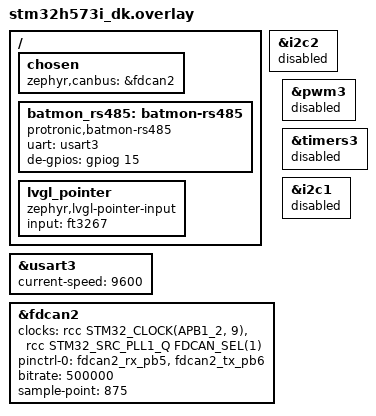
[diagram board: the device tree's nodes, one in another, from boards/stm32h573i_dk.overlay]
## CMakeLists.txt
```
cmake_minimum_required(VERSION 3.20.0)

find_package(Zephyr REQUIRED HINTS $ENV{ZEPHYR_BASE})
project(batmon LANGUAGES C VERSION 0.1.0)

target_include_directories(app PRIVATE src src/proto)

target_sources(app PRIVATE
  src/main.c
  src/can_rx.c
  src/proto/bm_proto.c
  src/proto/bm_json.c
  src/proto/bm_ydt.c
  src/proto/bm_serial.c
)

target_sources_ifdef(CONFIG_BATMON_RS485 app PRIVATE src/rs485.c)
target_sources_ifdef(CONFIG_BATMON_MQTT app PRIVATE src/net_mqtt.c)
target_sources_ifdef(CONFIG_BATMON_UI app PRIVATE src/ui.c)
target_sources_ifdef(CONFIG_SHELL app PRIVATE src/shell_cmds.c)
```

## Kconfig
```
mainmenu "batmon - battery CAN monitor"

menu "batmon"

config BATMON_DEVICE_ID
	string "Device id (MQTT client id, topic element, display)"
	default "batmon"

config BATMON_CAN_BITRATE
	int "CAN bitrate in bit/s"
	default 500000

config BATMON_CAN_LISTEN_ONLY
	bool "Listen-only: never acknowledge or transmit on the bus"
	default y
	help
	  Recommended when batmon is attached to a bus that already carries a
	  battery and an inverter. Disable only on the bench, where batmon is the
	  only counterpart of the battery.

config BATMON_BENCH_HEARTBEAT
	bool "Send the inverter keep-alive 0x305 once per second (bench mode)"
	depends on !BATMON_CAN_LISTEN_ONLY
	default n
	help
	  Many BMS firmwares stop reporting or open the contactor when no inverter
	  heartbeat is seen. With this option batmon plays the inverter role.

config BATMON_RAW_LOG
	bool "Log every received CAN frame"
	default n

config BATMON_MQTT
	bool "Publish telemetry over MQTT"
	default y

if BATMON_MQTT

config BATMON_MQTT_BROKER_HOST
	string "Broker host name or IPv4 address"
	default "192.168.1.10"

config BATMON_MQTT_BROKER_PORT
	int "Broker TCP port"
	default 1883

config BATMON_MQTT_USERNAME
	string "User name (ThingsBoard: device access token)"
	default ""

config BATMON_MQTT_PASSWORD
	string "Password"
	default ""

config BATMON_MQTT_INTERVAL_SEC
	int "Publish interval in seconds"
	default 5
	range 1 3600

choice BATMON_MQTT_MODE
	prompt "Topic and payload scheme"
	default BATMON_MQTT_MODE_GENERIC

config BATMON_MQTT_MODE_GENERIC
	bool "Generic: <prefix>/<id>/state JSON, <prefix>/<id>/status LWT"

config BATMON_MQTT_MODE_THINGSBOARD
	bool "ThingsBoard device API: v1/devices/me/telemetry (flat JSON)"

endchoice

config BATMON_MQTT_TOPIC_PREFIX
	string "Topic prefix (generic mode)"
	default "batmon"
	depends on BATMON_MQTT_MODE_GENERIC

config BATMON_HA_DISCOVERY
	bool "Publish Home Assistant MQTT discovery messages"
	default y
	depends on BATMON_MQTT_MODE_GENERIC

endif # BATMON_MQTT

menuconfig BATMON_RS485
	bool "RS485/UART BMS link (Pylontech/PACE/Seplos ASCII, JK-BMS, Seplos V3 Modbus)"
	default y
	depends on DT_HAS_PROTRONIC_BATMON_RS485_ENABLED
	select SERIAL
	select UART_INTERRUPT_DRIVEN
	select UART_USE_RUNTIME_CONFIGURE
	select RING_BUFFER
	help
	  Poll the BMS over its RS485 port (or listen to an inverter doing so) in
	  addition to the CAN bus. Needs a batmon-rs485 node in the devicetree.

if BATMON_RS485

config BATMON_RS485_LISTEN_ONLY
	bool "Listen only: decode the traffic between inverter and BMS, never transmit"
	default n

config BATMON_RS485_POLL_MS
	int "Poll interval in ms"
	default 2000
	range 200 60000

config BATMON_RS485_BAUD
	int "Fixed baud rate (0 = try 9600, 19200 and 115200)"
	default 0

config BATMON_RS485_ADDR
	int "Fixed pack address (-1 = try the usual ones)"
	default -1
	range -1 15
	help
	  Pylontech packs answer on address 2 (first module), PACE on 1,
	  Seplos on 0.

choice BATMON_RS485_FLAVOR
	prompt "Protocol"
	default BATMON_RS485_FLAVOR_AUTO

config BATMON_RS485_FLAVOR_AUTO
	bool "Auto-detect"

config BATMON_RS485_FLAVOR_PYLON
	bool "Pylontech ASCII (US2000/US3000/US5000, Force L)"

config BATMON_RS485_FLAVOR_PACE
	bool "PACE ASCII (FM-Solar/DelongTop, Gobel, SOK ...)"

config BATMON_RS485_FLAVOR_SEPLOS
	bool "Seplos V2 ASCII"

config BATMON_RS485_FLAVOR_JK
	bool "JK-BMS RS485"

config BATMON_RS485_FLAVOR_SEPLOS_V3
	bool "Seplos V3 Modbus RTU"

endchoice

config BATMON_JK_CURRENT_LEGACY
	bool "JK-BMS: old firmware current encoding (10000 - raw)"
	default n

endif # BATMON_RS485

config BATMON_UI
	bool "Status screen on the board display (LVGL)"
	default y
	depends on LVGL

endmenu

source "Kconfig.zephyr"
```

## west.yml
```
manifest:
  remotes:
    - name: zephyrproject-rtos
      url-base: https://github.com/zephyrproject-rtos

  projects:
    - name: zephyr
      remote: zephyrproject-rtos
      revision: v4.4.2
      import:
        name-allowlist:
          - cmsis
          - cmsis_6
          - hal_stm32
          - lvgl

  self:
    path: batmon
```

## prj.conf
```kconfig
# --- kernel / debug ---------------------------------------------------------
CONFIG_MAIN_STACK_SIZE=4096
CONFIG_SYSTEM_WORKQUEUE_STACK_SIZE=2048
CONFIG_HEAP_MEM_POOL_SIZE=24576
CONFIG_LOG=y
CONFIG_LOG_BUFFER_SIZE=4096
CONFIG_SHELL=y
CONFIG_SHELL_STACK_SIZE=4096
CONFIG_DEVICE_SHELL=y
CONFIG_KERNEL_SHELL=y
CONFIG_HWINFO=y
CONFIG_GPIO=y
CONFIG_REBOOT=y
CONFIG_ENTROPY_GENERATOR=y

# --- RS485 ------------------------------------------------------------------
CONFIG_SERIAL=y
CONFIG_UART_INTERRUPT_DRIVEN=y
CONFIG_RING_BUFFER=y

# --- CAN --------------------------------------------------------------------
CONFIG_CAN=y
CONFIG_CAN_SHELL=y

# --- Ethernet / IP ----------------------------------------------------------
CONFIG_NETWORKING=y
CONFIG_NET_L2_ETHERNET=y
CONFIG_NET_IPV4=y
CONFIG_NET_IPV6=n
CONFIG_NET_ARP=y
CONFIG_NET_UDP=y
CONFIG_NET_TCP=y
CONFIG_NET_DHCPV4=y
CONFIG_NET_SOCKETS=y
CONFIG_NET_SOCKETS_POLL_MAX=4
CONFIG_DNS_RESOLVER=y
CONFIG_NET_MGMT=y
CONFIG_NET_MGMT_EVENT=y
CONFIG_NET_MGMT_EVENT_INFO=y
CONFIG_NET_SHELL=y
CONFIG_NET_PKT_RX_COUNT=12
CONFIG_NET_PKT_TX_COUNT=12
CONFIG_NET_BUF_RX_COUNT=48
CONFIG_NET_BUF_TX_COUNT=48

# --- MQTT -------------------------------------------------------------------
CONFIG_MQTT_LIB=y
CONFIG_MQTT_KEEPALIVE=60

# --- display / LVGL ---------------------------------------------------------
CONFIG_DISPLAY=y
CONFIG_DISPLAY_LOG_LEVEL_ERR=y
CONFIG_INPUT=y
CONFIG_LVGL=y
CONFIG_LV_Z_MEM_POOL_SIZE=32768
CONFIG_LV_Z_VDB_SIZE=20
CONFIG_LV_COLOR_DEPTH_16=y
CONFIG_LV_USE_LABEL=y
CONFIG_LV_USE_BAR=y
CONFIG_LV_USE_ARC=y
CONFIG_LV_USE_CHART=y
CONFIG_LV_USE_BUTTON=y
CONFIG_LV_USE_TABVIEW=y
CONFIG_LV_FONT_MONTSERRAT_14=y
CONFIG_LV_FONT_MONTSERRAT_20=y
CONFIG_LV_FONT_MONTSERRAT_32=y
CONFIG_LV_FONT_DEFAULT_MONTSERRAT_14=y
```

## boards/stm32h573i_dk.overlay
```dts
/*
 * batmon on the STM32H573I-DK
 *
 * The Discovery kit has no CAN transceiver on board. FDCAN2 is routed to the
 * Arduino header, so a small 3.3 V transceiver breakout (SN65HVD230, TJA1051T/3,
 * MCP2562FD ...) connects directly:
 *
 *   PB5  FDCAN2_RX  -> Arduino D3   (transceiver RXD)
 *   PB6  FDCAN2_TX  -> Arduino D15  (transceiver TXD, the pin labelled SCL)
 *   3V3 / GND       -> transceiver supply (3.3 V logic!)
 *
 * PB5/PB6 are otherwise TIM3_CH2 (D3 PWM) and I2C1_SCL (Arduino I2C), both unused
 * by batmon and therefore disabled here.
 *
 * Alternative: the board devicetree wires FDCAN1 to PA11/PA12, which are shared
 * with the USB-C data lines. To use that instead, drop the fdcan2 block below,
 * set `zephyr,canbus = &fdcan1;`, add bitrate/sample-point to &fdcan1 and
 * disable &usb.
 *
 * RS485 (optional): USART3 on the Arduino header plus a 3.3 V RS485 transceiver
 * (MAX3485, SP3485, TI SN65HVD72 ...):
 *
 *   PB10 USART3_TX  -> Arduino D1  (transceiver DI)
 *   PB11 USART3_RX  -> Arduino D0  (transceiver RO)
 *   PG15 GPIO       -> Arduino D2  (transceiver DE and /RE tied together)
 *
 * Drop the de-gpios line for modules with automatic direction control. PB10/PB11
 * are shared with I2C2, which batmon does not use.
 */

#include <zephyr/dt-bindings/gpio/gpio.h>

/ {
	chosen {
		zephyr,canbus = &fdcan2;
	};

	batmon_rs485: batmon-rs485 {
		compatible = "protronic,batmon-rs485";
		uart = <&usart3>;
		de-gpios = <&gpiog 15 GPIO_ACTIVE_HIGH>;
	};

	/* touch panel -> LVGL pointer; add swap-xy / invert-x / invert-y here if the
	 * touch position is mirrored against the display */
	lvgl_pointer {
		compatible = "zephyr,lvgl-pointer-input";
		input = <&ft3267>;
	};
};

&usart3 {
	current-speed = <9600>;
};

&i2c2 {
	status = "disabled";
};

&fdcan2 {
	clocks = <&rcc STM32_CLOCK(APB1_2, 9)>,
		 <&rcc STM32_SRC_PLL1_Q FDCAN_SEL(1)>;
	pinctrl-0 = <&fdcan2_rx_pb5 &fdcan2_tx_pb6>;
	pinctrl-names = "default";
	bitrate = <500000>;
	sample-point = <875>;
	status = "okay";
};

&pwm3 {
	status = "disabled";
};

&timers3 {
	status = "disabled";
};

&i2c1 {
	status = "disabled";
};
```

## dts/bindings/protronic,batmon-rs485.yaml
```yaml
# batmon RS485 BMS port: the UART wired to an RS485 transceiver plus the optional
# driver-enable line (DE and /RE tied together). Leave de-gpios out for
# transceiver modules with automatic direction control.

description: batmon RS485 BMS port

compatible: "protronic,batmon-rs485"

properties:
  uart:
    type: phandle
    required: true
    description: UART controller connected to the RS485 transceiver

  de-gpios:
    type: phandle-array
    description: Driver enable output, active while batmon transmits
```

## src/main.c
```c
#include <zephyr/kernel.h>
#include <zephyr/device.h>
#include <zephyr/drivers/gpio.h>
#include <zephyr/logging/log.h>

#include <app_version.h>

#include "app.h"

LOG_MODULE_REGISTER(batmon, LOG_LEVEL_INF);

struct app_state app;

#if defined(CONFIG_BATMON_RS485_FLAVOR_PYLON)
#define RS485_FIXED_FLAVOR BM_SER_PYLON_ASCII
#elif defined(CONFIG_BATMON_RS485_FLAVOR_PACE)
#define RS485_FIXED_FLAVOR BM_SER_PACE_ASCII
#elif defined(CONFIG_BATMON_RS485_FLAVOR_SEPLOS)
#define RS485_FIXED_FLAVOR BM_SER_SEPLOS_ASCII
#elif defined(CONFIG_BATMON_RS485_FLAVOR_JK)
#define RS485_FIXED_FLAVOR BM_SER_JK_BIN
#elif defined(CONFIG_BATMON_RS485_FLAVOR_SEPLOS_V3)
#define RS485_FIXED_FLAVOR BM_SER_SEPLOS_MODBUS
#else
#define RS485_FIXED_FLAVOR BM_SER_NONE
#endif

static const struct gpio_dt_spec led = GPIO_DT_SPEC_GET_OR(DT_ALIAS(led0), gpios, {0});

void app_proto_snapshot(struct bm_proto *dst)
{
	k_mutex_lock(&app.lock, K_FOREVER);
	*dst = app.proto;
	k_mutex_unlock(&app.lock);
}

void app_serial_snapshot(struct bm_serial *dst)
{
	k_mutex_lock(&app.lock, K_FOREVER);
	*dst = app.serial;
	k_mutex_unlock(&app.lock);
}

int app_json(char *buf, size_t len, bool flat)
{
	k_mutex_lock(&app.lock, K_FOREVER);
	const struct bm_serial *ser = app.rs485_present ? &app.serial : NULL;
	int n = flat ? bm_json_flat_ex(&app.proto, ser, app_uptime_ms(), buf, len)
		     : bm_json_telemetry_ex(&app.proto, ser, app_uptime_ms(), buf, len);
	k_mutex_unlock(&app.lock);
	return n;
}

int main(void)
{
	k_mutex_init(&app.lock);
	bm_proto_init(&app.proto);
#ifdef CONFIG_BATMON_RS485
	struct bm_serial_cfg scfg = {
		.poll_ms = CONFIG_BATMON_RS485_POLL_MS,
		.fixed_baud = CONFIG_BATMON_RS485_BAUD,
		.fixed_addr = CONFIG_BATMON_RS485_ADDR,
		.fixed_flavor = RS485_FIXED_FLAVOR,
		.jk_current_legacy = IS_ENABLED(CONFIG_BATMON_JK_CURRENT_LEGACY),
	};

	bm_serial_init(&app.serial, &scfg);
#else
	bm_serial_init(&app.serial, NULL);
#endif
	app.raw_log = IS_ENABLED(CONFIG_BATMON_RAW_LOG);
	app.bench_heartbeat = IS_ENABLED(CONFIG_BATMON_BENCH_HEARTBEAT);

	if (led.port != NULL && device_is_ready(led.port)) {
		gpio_pin_configure_dt(&led, GPIO_OUTPUT_INACTIVE);
	}

	LOG_INF("batmon %s starting, device id %s", APP_VERSION_STRING, CONFIG_BATMON_DEVICE_ID);

	int rc = can_rx_init();

	if (rc) {
		LOG_ERR("CAN init failed (%d)", rc);
	}
#ifdef CONFIG_BATMON_RS485
	rc = rs485_init();
	if (rc) {
		LOG_ERR("RS485 init failed (%d)", rc);
	}
#endif
#ifdef CONFIG_BATMON_UI
	rc = ui_init();
	if (rc) {
		LOG_ERR("UI init failed (%d)", rc);
	}
#endif
#ifdef CONFIG_BATMON_MQTT
	rc = net_mqtt_init();
	if (rc) {
		LOG_ERR("network init failed (%d)", rc);
	}
#endif

	bool on = false;

	while (1) {
		k_mutex_lock(&app.lock, K_FOREVER);
		bm_proto_tick(&app.proto, app_uptime_ms());
		bool link = app.proto.link_up;
		k_mutex_unlock(&app.lock);

		/* LED: steady when battery frames arrive, blinking while waiting */
		if (led.port != NULL) {
			on = link ? true : !on;
			gpio_pin_set_dt(&led, on);
		}
		k_sleep(K_MSEC(link ? 1000 : 500));
	}
	return 0;
}
```

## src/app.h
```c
#ifndef BATMON_APP_H
#define BATMON_APP_H

#include <zephyr/kernel.h>
#include <zephyr/drivers/can.h>

#include "bm_proto.h"
#include "bm_serial.h"

#define APP_JSON_MAX 2560

struct app_state {
	struct k_mutex lock;
	struct bm_proto proto;
	struct bm_serial serial;
	bool rs485_present;

	/* CAN */
	enum can_state can_state;
	uint32_t can_rx_total;
	uint32_t can_rx_dropped;
	uint32_t can_tx_errors;
	bool raw_log;
	bool bench_heartbeat;

	/* network */
	bool net_up;
	char ip[16];
	bool mqtt_connected;
	uint32_t mqtt_pub_count;
	uint32_t mqtt_errors;
};

extern struct app_state app;

static inline uint32_t app_uptime_ms(void)
{
	return k_uptime_get_32();
}

/* Snapshots of the protocol states under lock. */
void app_proto_snapshot(struct bm_proto *dst);
void app_serial_snapshot(struct bm_serial *dst);

/* Telemetry JSON (nested or flat) built under lock; returns length or -1. */
int app_json(char *buf, size_t len, bool flat);

/* can_rx.c */
int can_rx_init(void);
int can_rx_set_heartbeat(bool enable);
const struct device *can_rx_device(void);

/* rs485.c */
int rs485_init(void);
/* One request/response on the bus (shell). Returns reply length, 0 on timeout, -errno. */
int rs485_transact(const uint8_t *tx, size_t tx_len, enum bm_ser_kind kind, uint32_t baud,
		   uint8_t *rx, size_t rx_max, uint32_t timeout_ms);

/* net_mqtt.c */
int net_mqtt_init(void);
int net_mqtt_publish_now(void);

/* ui.c */
int ui_init(void);

#endif /* BATMON_APP_H */
```

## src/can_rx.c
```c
#include <zephyr/kernel.h>
#include <zephyr/device.h>
#include <zephyr/drivers/can.h>
#include <zephyr/logging/log.h>

#include "app.h"

LOG_MODULE_REGISTER(batmon_can, LOG_LEVEL_INF);

#define RX_QUEUE_LEN     64
#define RX_THREAD_STACK  2048
#define RX_THREAD_PRIO   5

struct rx_item {
	struct can_frame frame;
	uint32_t ms;
};

K_MSGQ_DEFINE(rx_msgq, sizeof(struct rx_item), RX_QUEUE_LEN, 4);
static K_THREAD_STACK_DEFINE(can_rx_stack, RX_THREAD_STACK);
static struct k_thread rx_thread_data;

static const struct device *const can_dev = DEVICE_DT_GET(DT_CHOSEN(zephyr_canbus));

const struct device *can_rx_device(void)
{
	return can_dev;
}

static void rx_cb(const struct device *dev, struct can_frame *frame, void *user_data)
{
	ARG_UNUSED(dev);
	ARG_UNUSED(user_data);
	struct rx_item item = { .frame = *frame, .ms = k_uptime_get_32() };

	if (k_msgq_put(&rx_msgq, &item, K_NO_WAIT) != 0) {
		app.can_rx_dropped++;
	}
}

static void state_cb(const struct device *dev, enum can_state state, struct can_bus_err_cnt err_cnt,
		     void *user_data)
{
	ARG_UNUSED(dev);
	ARG_UNUSED(user_data);
	app.can_state = state;
	LOG_WRN("CAN state %d (tx err %u, rx err %u)", state, err_cnt.tx_err_cnt, err_cnt.rx_err_cnt);
}

static void heartbeat_work_fn(struct k_work *work);
static K_WORK_DELAYABLE_DEFINE(heartbeat_work, heartbeat_work_fn);

static void heartbeat_work_fn(struct k_work *work)
{
	ARG_UNUSED(work);
	if (!app.bench_heartbeat) {
		return;
	}
	struct can_frame frame = { .id = 0x305, .dlc = 8, .flags = 0 };

	bm_build_heartbeat(frame.data);
	int rc = can_send(can_dev, &frame, K_MSEC(50), NULL, NULL);

	if (rc != 0) {
		app.can_tx_errors++;
	}
	k_work_schedule(&heartbeat_work, K_SECONDS(1));
}

int can_rx_set_heartbeat(bool enable)
{
	if (IS_ENABLED(CONFIG_BATMON_CAN_LISTEN_ONLY)) {
		return -EACCES;
	}
	app.bench_heartbeat = enable;
	if (enable) {
		k_work_schedule(&heartbeat_work, K_NO_WAIT);
	} else {
		k_work_cancel_delayable(&heartbeat_work);
	}
	return 0;
}

static void rx_thread(void *a, void *b, void *c)
{
	ARG_UNUSED(a);
	ARG_UNUSED(b);
	ARG_UNUSED(c);
	struct rx_item item;

	while (1) {
		if (k_msgq_get(&rx_msgq, &item, K_MSEC(500)) != 0) {
			continue;
		}
		const struct can_frame *f = &item.frame;

		if (f->flags & CAN_FRAME_RTR) {
			continue;
		}
		bool ext = (f->flags & CAN_FRAME_IDE) != 0;
		uint8_t len = can_dlc_to_bytes(f->dlc);

		if (len > 8) {
			len = 8;
		}
		app.can_rx_total++;
		if (app.raw_log) {
			LOG_INF("rx %s%03x [%u] %02x %02x %02x %02x %02x %02x %02x %02x",
				ext ? "x" : "", (unsigned int)f->id, len, f->data[0], f->data[1],
				f->data[2], f->data[3], f->data[4], f->data[5], f->data[6], f->data[7]);
		}
		k_mutex_lock(&app.lock, K_FOREVER);
		bm_proto_feed(&app.proto, f->id, ext, f->data, len, item.ms);
		k_mutex_unlock(&app.lock);
	}
}

int can_rx_init(void)
{
	if (!device_is_ready(can_dev)) {
		LOG_ERR("CAN device not ready");
		return -ENODEV;
	}
	int rc = can_set_bitrate(can_dev, CONFIG_BATMON_CAN_BITRATE);

	if (rc) {
		LOG_ERR("can_set_bitrate(%d): %d", CONFIG_BATMON_CAN_BITRATE, rc);
		return rc;
	}
	can_mode_t mode = IS_ENABLED(CONFIG_BATMON_CAN_LISTEN_ONLY) ? CAN_MODE_LISTENONLY
								     : CAN_MODE_NORMAL;

	rc = can_set_mode(can_dev, mode);
	if (rc) {
		LOG_ERR("can_set_mode: %d", rc);
		return rc;
	}
	can_set_state_change_callback(can_dev, state_cb, NULL);

	const struct can_filter std = { .id = 0, .mask = 0, .flags = 0 };
	const struct can_filter ext = { .id = 0, .mask = 0, .flags = CAN_FILTER_IDE };

	if (can_add_rx_filter(can_dev, rx_cb, NULL, &std) < 0 ||
	    can_add_rx_filter(can_dev, rx_cb, NULL, &ext) < 0) {
		LOG_ERR("cannot add rx filters");
		return -EIO;
	}
	rc = can_start(can_dev);
	if (rc) {
		LOG_ERR("can_start: %d", rc);
		return rc;
	}
	k_thread_create(&rx_thread_data, can_rx_stack, K_THREAD_STACK_SIZEOF(can_rx_stack), rx_thread, NULL,
			NULL, NULL, RX_THREAD_PRIO, 0, K_NO_WAIT);
	k_thread_name_set(&rx_thread_data, "can_rx");

	if (app.bench_heartbeat) {
		can_rx_set_heartbeat(true);
	}
	LOG_INF("CAN %s at %d bit/s, %s", can_dev->name, CONFIG_BATMON_CAN_BITRATE,
		mode == CAN_MODE_LISTENONLY ? "listen-only" : "normal mode");
	return 0;
}
```

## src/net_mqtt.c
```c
#include <zephyr/kernel.h>
#include <zephyr/logging/log.h>
#include <zephyr/net/net_if.h>
#include <zephyr/net/net_mgmt.h>
#include <zephyr/net/net_event.h>
#include <zephyr/net/dhcpv4.h>
#include <zephyr/net/socket.h>
#include <zephyr/net/mqtt.h>
#include <zephyr/random/random.h>

#include <stdio.h>
#include <string.h>

#include "app.h"

LOG_MODULE_REGISTER(batmon_net, LOG_LEVEL_INF);

#define MQTT_THREAD_STACK 4096
#define MQTT_THREAD_PRIO  7
#define RX_BUF_SIZE       512
#define TX_BUF_SIZE       4096
#define RECONNECT_MIN_MS  2000
#define RECONNECT_MAX_MS  60000

static K_THREAD_STACK_DEFINE(batmon_mqtt_stack, MQTT_THREAD_STACK);
static struct k_thread mqtt_thread_data;
static K_SEM_DEFINE(net_ready, 0, 1);
static K_SEM_DEFINE(publish_req, 0, 1);

static struct net_mgmt_event_callback mgmt_cb;
static struct mqtt_client client;
static struct sockaddr_storage broker;
static uint8_t rx_buf[RX_BUF_SIZE];
static uint8_t tx_buf[TX_BUF_SIZE];
static char payload[APP_JSON_MAX];
static bool connected;

#ifdef CONFIG_BATMON_MQTT_MODE_THINGSBOARD
#define TOPIC_TELEMETRY "v1/devices/me/telemetry"
#define TOPIC_ATTRS     "v1/devices/me/attributes"
#else
#define TOPIC_PREFIX    CONFIG_BATMON_MQTT_TOPIC_PREFIX "/" CONFIG_BATMON_DEVICE_ID
#define TOPIC_STATE     TOPIC_PREFIX "/state"
#define TOPIC_STATUS    TOPIC_PREFIX "/status"
#endif

static void net_event(struct net_mgmt_event_callback *cb, uint64_t event, struct net_if *iface)
{
	ARG_UNUSED(cb);
	if (event == NET_EVENT_IPV4_ADDR_ADD) {
		struct in_addr *addr = net_if_ipv4_get_global_addr(iface, NET_ADDR_PREFERRED);

		if (addr) {
			net_addr_ntop(AF_INET, addr, app.ip, sizeof(app.ip));
		}
		app.net_up = true;
		LOG_INF("IPv4 address %s", app.ip);
		k_sem_give(&net_ready);
	} else if (event == NET_EVENT_IF_DOWN) {
		app.net_up = false;
		LOG_WRN("network interface down");
	}
}

static void mqtt_evt(struct mqtt_client *c, const struct mqtt_evt *evt)
{
	ARG_UNUSED(c);
	switch (evt->type) {
	case MQTT_EVT_CONNACK:
		if (evt->result == 0) {
			connected = true;
			app.mqtt_connected = true;
			LOG_INF("MQTT connected");
		} else {
			LOG_ERR("MQTT connect refused (%d)", evt->result);
		}
		break;
	case MQTT_EVT_DISCONNECT:
		connected = false;
		app.mqtt_connected = false;
		LOG_WRN("MQTT disconnected (%d)", evt->result);
		break;
	case MQTT_EVT_PUBACK:
	case MQTT_EVT_PINGRESP:
	default:
		break;
	}
}

static int resolve_broker(void)
{
	struct zsock_addrinfo hints = { .ai_family = AF_INET, .ai_socktype = SOCK_STREAM };
	struct zsock_addrinfo *res = NULL;
	char port[8];

	snprintf(port, sizeof(port), "%d", CONFIG_BATMON_MQTT_BROKER_PORT);
	int rc = zsock_getaddrinfo(CONFIG_BATMON_MQTT_BROKER_HOST, port, &hints, &res);

	if (rc != 0 || res == NULL) {
		LOG_ERR("cannot resolve %s (%d)", CONFIG_BATMON_MQTT_BROKER_HOST, rc);
		return -EHOSTUNREACH;
	}
	memcpy(&broker, res->ai_addr, MIN(res->ai_addrlen, sizeof(broker)));
	zsock_freeaddrinfo(res);
	return 0;
}

static int publish(const char *topic, const char *data, size_t len, bool retain)
{
	struct mqtt_publish_param param = {
		.message.topic.topic.utf8 = (uint8_t *)topic,
		.message.topic.topic.size = strlen(topic),
		.message.topic.qos = MQTT_QOS_0_AT_MOST_ONCE,
		.message.payload.data = (uint8_t *)data,
		.message.payload.len = len,
		.message_id = (uint16_t)sys_rand32_get(),
		.dup_flag = 0,
		.retain_flag = retain ? 1 : 0,
	};
	int rc = mqtt_publish(&client, &param);

	if (rc) {
		app.mqtt_errors++;
	} else {
		app.mqtt_pub_count++;
	}
	return rc;
}

#if defined(CONFIG_BATMON_HA_DISCOVERY)
struct ha_entity {
	const char *key;
	const char *name;
	const char *tpl;
	const char *unit;
	const char *dev_class;
};

static const struct ha_entity ha_entities[] = {
	{ "soc", "SoC", "{{ value_json.pack.soc }}", "%", "battery" },
	{ "soh", "SoH", "{{ value_json.pack.soh }}", "%", NULL },
	{ "voltage", "Spannung", "{{ value_json.pack.u }}", "V", "voltage" },
	{ "current", "Strom", "{{ value_json.pack.i }}", "A", "current" },
	{ "temperature", "Temperatur", "{{ value_json.pack.t }}", "°C", "temperature" },
	{ "cvl", "Ladespannungsgrenze", "{{ value_json.pack.cvl }}", "V", "voltage" },
	{ "ccl", "Ladestromgrenze", "{{ value_json.pack.ccl }}", "A", "current" },
	{ "dcl", "Entladestromgrenze", "{{ value_json.pack.dcl }}", "A", "current" },
	{ "flavor", "Protokoll", "{{ value_json.proto.flavor }}", NULL, NULL },
	{ "manufacturer", "Hersteller", "{{ value_json.proto.mfr }}", NULL, NULL },
};

static void publish_ha_discovery(void)
{
	for (size_t i = 0; i < ARRAY_SIZE(ha_entities); i++) {
		const struct ha_entity *e = &ha_entities[i];
		char topic[96];

		snprintf(topic, sizeof(topic), "homeassistant/sensor/%s_%s/config",
			 CONFIG_BATMON_DEVICE_ID, e->key);
		int n = snprintf(payload, sizeof(payload),
				 "{\"name\":\"%s\",\"uniq_id\":\"%s_%s\",\"stat_t\":\"%s\","
				 "\"val_tpl\":\"%s\",\"avty_t\":\"%s\","
				 "\"dev\":{\"ids\":[\"%s\"],\"name\":\"batmon %s\","
				 "\"mf\":\"PROTRONIC\",\"mdl\":\"batmon STM32H573I-DK\"}",
				 e->name, CONFIG_BATMON_DEVICE_ID, e->key, TOPIC_STATE, e->tpl,
				 TOPIC_STATUS, CONFIG_BATMON_DEVICE_ID, CONFIG_BATMON_DEVICE_ID);
		if (e->unit) {
			n += snprintf(payload + n, sizeof(payload) - n, ",\"unit_of_meas\":\"%s\"",
				      e->unit);
		}
		if (e->dev_class) {
			n += snprintf(payload + n, sizeof(payload) - n, ",\"dev_cla\":\"%s\"",
				      e->dev_class);
		}
		n += snprintf(payload + n, sizeof(payload) - n, "}");
		publish(topic, payload, n, true);
		mqtt_input(&client);
	}
}
#endif

static int connect_broker(void)
{
	int rc = resolve_broker();

	if (rc) {
		return rc;
	}
	mqtt_client_init(&client);
	client.broker = &broker;
	client.evt_cb = mqtt_evt;
	client.client_id.utf8 = (uint8_t *)CONFIG_BATMON_DEVICE_ID;
	client.client_id.size = strlen(CONFIG_BATMON_DEVICE_ID);
	client.protocol_version = MQTT_VERSION_3_1_1;
	client.rx_buf = rx_buf;
	client.rx_buf_size = sizeof(rx_buf);
	client.tx_buf = tx_buf;
	client.tx_buf_size = sizeof(tx_buf);
	client.transport.type = MQTT_TRANSPORT_NON_SECURE;
	client.clean_session = 1;

	static struct mqtt_utf8 user, pass;

	if (strlen(CONFIG_BATMON_MQTT_USERNAME) > 0) {
		user.utf8 = (uint8_t *)CONFIG_BATMON_MQTT_USERNAME;
		user.size = strlen(CONFIG_BATMON_MQTT_USERNAME);
		client.user_name = &user;
	}
	if (strlen(CONFIG_BATMON_MQTT_PASSWORD) > 0) {
		pass.utf8 = (uint8_t *)CONFIG_BATMON_MQTT_PASSWORD;
		pass.size = strlen(CONFIG_BATMON_MQTT_PASSWORD);
		client.password = &pass;
	}
#ifndef CONFIG_BATMON_MQTT_MODE_THINGSBOARD
	static struct mqtt_topic will_topic = {
		.topic = { .utf8 = (uint8_t *)TOPIC_STATUS, .size = sizeof(TOPIC_STATUS) - 1 },
		.qos = MQTT_QOS_0_AT_MOST_ONCE,
	};
	static struct mqtt_utf8 will_msg = { .utf8 = (uint8_t *)"offline", .size = 7 };

	client.will_topic = &will_topic;
	client.will_message = &will_msg;
	client.will_retain = 1;
#endif
	rc = mqtt_connect(&client);
	if (rc) {
		LOG_ERR("mqtt_connect: %d", rc);
		return rc;
	}
	/* wait for CONNACK */
	struct zsock_pollfd fd = { .fd = client.transport.tcp.sock, .events = ZSOCK_POLLIN };

	for (int i = 0; i < 10 && !connected; i++) {
		if (zsock_poll(&fd, 1, 500) > 0) {
			mqtt_input(&client);
		}
	}
	if (!connected) {
		mqtt_abort(&client);
		return -ETIMEDOUT;
	}
#ifndef CONFIG_BATMON_MQTT_MODE_THINGSBOARD
	publish(TOPIC_STATUS, "online", 6, true);
#if defined(CONFIG_BATMON_HA_DISCOVERY)
	publish_ha_discovery();
#endif
#else
	int n = snprintf(payload, sizeof(payload),
			 "{\"fw\":\"%s\",\"board\":\"%s\",\"device_id\":\"%s\"}", APP_VERSION_STRING,
			 CONFIG_BOARD, CONFIG_BATMON_DEVICE_ID);
	publish(TOPIC_ATTRS, payload, n, false);
#endif
	return 0;
}

static int publish_telemetry(void)
{
#ifdef CONFIG_BATMON_MQTT_MODE_THINGSBOARD
	int n = app_json(payload, sizeof(payload), true);
	const char *topic = TOPIC_TELEMETRY;
#else
	int n = app_json(payload, sizeof(payload), false);
	const char *topic = TOPIC_STATE;
#endif
	if (n < 0) {
		LOG_ERR("telemetry JSON too large");
		return -ENOMEM;
	}
	return publish(topic, payload, n, false);
}

int net_mqtt_publish_now(void)
{
	k_sem_give(&publish_req);
	return 0;
}

static void mqtt_thread(void *a, void *b, void *c)
{
	ARG_UNUSED(a);
	ARG_UNUSED(b);
	ARG_UNUSED(c);
	uint32_t backoff = RECONNECT_MIN_MS;

	k_sem_take(&net_ready, K_FOREVER);

	while (1) {
		if (connect_broker() != 0) {
			LOG_WRN("broker %s:%d unreachable, retry in %u ms",
				CONFIG_BATMON_MQTT_BROKER_HOST, CONFIG_BATMON_MQTT_BROKER_PORT, backoff);
			k_sleep(K_MSEC(backoff));
			backoff = MIN(backoff * 2, RECONNECT_MAX_MS);
			continue;
		}
		backoff = RECONNECT_MIN_MS;
		int64_t next_pub = k_uptime_get();

		while (connected) {
			struct zsock_pollfd fd = { .fd = client.transport.tcp.sock,
						   .events = ZSOCK_POLLIN };
			int64_t wait = next_pub - k_uptime_get();

			if (wait < 0) {
				wait = 0;
			}
			int rc = zsock_poll(&fd, 1, (int)MIN(wait, 1000));

			if (rc > 0) {
				if (mqtt_input(&client) != 0) {
					break;
				}
			} else if (rc < 0) {
				break;
			}
			if (k_sem_take(&publish_req, K_NO_WAIT) == 0 || k_uptime_get() >= next_pub) {
				if (publish_telemetry() != 0) {
					break;
				}
				next_pub = k_uptime_get() + CONFIG_BATMON_MQTT_INTERVAL_SEC * 1000;
			}
			rc = mqtt_live(&client);
			if (rc != 0 && rc != -EAGAIN) {
				break;
			}
		}
		mqtt_abort(&client);
		connected = false;
		app.mqtt_connected = false;
		k_sleep(K_MSEC(backoff));
	}
}

int net_mqtt_init(void)
{
	struct net_if *iface = net_if_get_default();

	if (iface == NULL) {
		return -ENODEV;
	}
	net_mgmt_init_event_callback(&mgmt_cb, net_event,
				     NET_EVENT_IPV4_ADDR_ADD | NET_EVENT_IF_DOWN);
	net_mgmt_add_event_callback(&mgmt_cb);
	net_dhcpv4_start(iface);

	k_thread_create(&mqtt_thread_data, batmon_mqtt_stack, K_THREAD_STACK_SIZEOF(batmon_mqtt_stack), mqtt_thread,
			NULL, NULL, NULL, MQTT_THREAD_PRIO, 0, K_NO_WAIT);
	k_thread_name_set(&mqtt_thread_data, "mqtt");
	LOG_INF("DHCP started, MQTT broker %s:%d", CONFIG_BATMON_MQTT_BROKER_HOST,
		CONFIG_BATMON_MQTT_BROKER_PORT);
	return 0;
}
```

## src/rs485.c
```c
/*
 * RS485 link to the BMS: interrupt driven UART receive into a ring buffer,
 * polled transmit with a driver-enable GPIO, request/response framing for the
 * YD/T ASCII, JK binary and Modbus RTU protocols, and a listen-only mode that
 * decodes the traffic between an inverter and the BMS.
 */
#include <zephyr/kernel.h>
#include <zephyr/device.h>
#include <zephyr/devicetree.h>
#include <zephyr/drivers/uart.h>
#include <zephyr/drivers/gpio.h>
#include <zephyr/sys/ring_buffer.h>
#include <zephyr/logging/log.h>

#include "app.h"

LOG_MODULE_REGISTER(batmon_rs485, LOG_LEVEL_INF);

#define RS485_NODE DT_COMPAT_GET_ANY_STATUS_OKAY(protronic_batmon_rs485)

#define RX_RING_SIZE   2048
#define THREAD_STACK   4096
#define THREAD_PRIO    6
#define INTERBYTE_MS   120   /* ASCII/JK: give up a half received frame after this gap */
#define IDLE_GAP_MS    15    /* Modbus / unknown: frame ends after this silence */
#define SNIFF_WAIT_MS  1000
#define SNIFF_ROTATE_MS 6000 /* listen-only: try the next baud rate when nothing decodes */
#define SNIFF_LOST_MS  20000

static const struct device *const uart_dev = DEVICE_DT_GET(DT_PHANDLE(RS485_NODE, uart));
static const struct gpio_dt_spec de_gpio = GPIO_DT_SPEC_GET_OR(RS485_NODE, de_gpios, {0});

RING_BUF_DECLARE(rs485_rx_rb, RX_RING_SIZE);
static K_SEM_DEFINE(rx_sem, 0, 1);
static K_MUTEX_DEFINE(bus_lock);
static volatile bool rx_discard;
static uint32_t cur_baud;
static uint8_t frame_buf[BM_SER_MAX_FRAME];

static K_THREAD_STACK_DEFINE(batmon_rs485_stack, THREAD_STACK);
static struct k_thread rs485_thread_data;

static void uart_isr(const struct device *dev, void *user_data)
{
	ARG_UNUSED(user_data);
	uint8_t tmp[32];

	while (uart_irq_update(dev) > 0 && uart_irq_is_pending(dev) > 0) {
		if (uart_irq_rx_ready(dev) <= 0) {
			break;
		}
		int n = uart_fifo_read(dev, tmp, sizeof(tmp));

		if (n <= 0) {
			break;
		}
		if (!rx_discard) {
			ring_buf_put(&rs485_rx_rb, tmp, (uint32_t)n);
			k_sem_give(&rx_sem);
		}
	}
}

static void rx_flush(void)
{
	ring_buf_reset(&rs485_rx_rb);
	k_sem_reset(&rx_sem);
}

/* One byte or -EAGAIN once the absolute deadline (uptime ms) passes. */
static int rx_byte(uint8_t *b, int64_t deadline)
{
	while (1) {
		if (ring_buf_get(&rs485_rx_rb, b, 1) == 1) {
			return 0;
		}
		int64_t left = deadline - k_uptime_get();

		if (left <= 0) {
			return -EAGAIN;
		}
		k_sem_take(&rx_sem, K_MSEC(left));
	}
}

static int set_baud(uint32_t baud)
{
	if (baud == 0 || baud == cur_baud) {
		return 0;
	}
	struct uart_config cfg = {
		.baudrate = baud,
		.parity = UART_CFG_PARITY_NONE,
		.stop_bits = UART_CFG_STOP_BITS_1,
		.data_bits = UART_CFG_DATA_BITS_8,
		.flow_ctrl = UART_CFG_FLOW_CTRL_NONE,
	};
	int rc = uart_configure(uart_dev, &cfg);

	if (rc) {
		LOG_ERR("uart_configure(%u): %d", baud, rc);
		return rc;
	}
	cur_baud = baud;
	return 0;
}

static void tx_frame(const uint8_t *d, size_t n)
{
	rx_discard = true;
	rx_flush();
	if (de_gpio.port != NULL) {
		gpio_pin_set_dt(&de_gpio, 1);
	}
	for (size_t i = 0; i < n; i++) {
		uart_poll_out(uart_dev, d[i]);
	}
	/* uart_poll_out returns once the byte is queued: wait two character times */
	k_sleep(K_USEC(20000000u / (cur_baud ? cur_baud : 9600) + 200));
	if (de_gpio.port != NULL) {
		gpio_pin_set_dt(&de_gpio, 0);
	}
	rx_discard = false;
	rx_flush();
}

static int64_t min_deadline(int64_t a, int64_t b)
{
	return a < b ? a : b;
}

/* Collect one reply of the given kind. Returns its length, 0 on timeout. */
static size_t collect(enum bm_ser_kind kind, size_t expect, uint32_t timeout_ms, uint8_t *buf,
		      size_t max)
{
	int64_t deadline = k_uptime_get() + timeout_ms;
	size_t n = 0;
	uint8_t b;

	switch (kind) {
	case BM_SER_KIND_ASCII:
		do {
			if (rx_byte(&b, deadline)) {
				return 0;
			}
		} while (b != '~');
		buf[n++] = b;
		while (n < max) {
			if (rx_byte(&b, min_deadline(deadline, k_uptime_get() + INTERBYTE_MS))) {
				return 0;
			}
			buf[n++] = b;
			if (b == '\r') {
				return n;
			}
		}
		return 0;

	case BM_SER_KIND_JK:
		while (1) {
			if (rx_byte(&b, deadline)) {
				return 0;
			}
			if (b != 0x4E) {
				continue;
			}
			if (rx_byte(&b, min_deadline(deadline, k_uptime_get() + INTERBYTE_MS))) {
				return 0;
			}
			if (b == 0x57) {
				break;
			}
		}
		buf[0] = 0x4E;
		buf[1] = 0x57;
		n = 2;
		while (n < 4) {
			if (rx_byte(&buf[n], min_deadline(deadline, k_uptime_get() + INTERBYTE_MS))) {
				return 0;
			}
			n++;
		}
		size_t total = ((size_t)buf[2] << 8 | buf[3]) + 2;

		if (total > max || total < 21) {
			return 0;
		}
		while (n < total) {
			if (rx_byte(&buf[n], min_deadline(deadline, k_uptime_get() + INTERBYTE_MS))) {
				return 0;
			}
			n++;
		}
		return n;

	default: /* Modbus: fixed length when known, else idle gap */
		if (rx_byte(&b, deadline)) {
			return 0;
		}
		buf[n++] = b;
		while (n < max && (expect == 0 || n < expect)) {
			if (rx_byte(&b, min_deadline(deadline, k_uptime_get() + IDLE_GAP_MS))) {
				break;
			}
			buf[n++] = b;
		}
		return n;
	}
}

/* Listen-only: any frame on the bus, framed by its own syntax or an idle gap. */
static size_t collect_any(uint8_t *buf, size_t max, uint32_t wait_ms)
{
	int64_t deadline = k_uptime_get() + wait_ms;
	size_t n = 0;
	uint8_t b;

	if (rx_byte(&b, deadline)) {
		return 0;
	}
	buf[n++] = b;
	if (b == '~') {
		while (n < max) {
			if (rx_byte(&b, k_uptime_get() + INTERBYTE_MS)) {
				return 0;
			}
			buf[n++] = b;
			if (b == '\r') {
				return n;
			}
		}
		return 0;
	}
	while (n < max) {
		if (rx_byte(&b, k_uptime_get() + IDLE_GAP_MS)) {
			break;
		}
		buf[n++] = b;
		if (n == 4 && buf[0] == 0x4E && buf[1] == 0x57) {
			size_t total = ((size_t)buf[2] << 8 | buf[3]) + 2;

			if (total > max) {
				return 0;
			}
			while (n < total) {
				if (rx_byte(&buf[n], k_uptime_get() + INTERBYTE_MS)) {
					return 0;
				}
				n++;
			}
			return n;
		}
	}
	return n;
}

int rs485_transact(const uint8_t *tx, size_t tx_len, enum bm_ser_kind kind, uint32_t baud,
		   uint8_t *rx, size_t rx_max, uint32_t timeout_ms)
{
	if (IS_ENABLED(CONFIG_BATMON_RS485_LISTEN_ONLY)) {
		return -EACCES;
	}
	k_mutex_lock(&bus_lock, K_FOREVER);
	int rc = set_baud(baud);

	if (rc) {
		k_mutex_unlock(&bus_lock);
		return rc;
	}
	tx_frame(tx, tx_len);
	size_t n = collect(kind, 0, timeout_ms, rx, rx_max);

	k_mutex_unlock(&bus_lock);
	return (int)n;
}

static void poll_loop(void)
{
	struct bm_serial_req req;

	while (1) {
		uint32_t now = app_uptime_ms();

		k_mutex_lock(&app.lock, K_FOREVER);
		int have = bm_serial_next_request(&app.serial, now, &req);

		k_mutex_unlock(&app.lock);
		if (!have) {
			k_sleep(K_MSEC(20));
			continue;
		}
		k_mutex_lock(&bus_lock, K_FOREVER);
		set_baud(req.baud);
		tx_frame(req.data, req.len);
		size_t n = collect(req.kind, req.expect_len, req.timeout_ms, frame_buf,
				   sizeof(frame_buf));

		k_mutex_unlock(&bus_lock);
		k_mutex_lock(&app.lock, K_FOREVER);
		bm_serial_response(&app.serial, frame_buf, n, app_uptime_ms());
		k_mutex_unlock(&app.lock);
	}
}

static void sniff_loop(void)
{
	static const uint32_t bauds[] = { 9600, 115200, 19200 };
	unsigned int idx = 0;

	while (1) {
		uint32_t baud = CONFIG_BATMON_RS485_BAUD ? CONFIG_BATMON_RS485_BAUD : bauds[idx];

		set_baud(baud);
		rx_flush();
		int64_t start = k_uptime_get(), last_ok = 0;
		unsigned int ok = 0;

		LOG_INF("listening at %u bit/s", baud);
		while (1) {
			size_t n = collect_any(frame_buf, sizeof(frame_buf), SNIFF_WAIT_MS);

			if (n) {
				k_mutex_lock(&app.lock, K_FOREVER);
				int good = bm_serial_sniff(&app.serial, frame_buf, n, app_uptime_ms());

				k_mutex_unlock(&app.lock);
				if (good) {
					ok++;
					last_ok = k_uptime_get();
				}
			}
			if (CONFIG_BATMON_RS485_BAUD) {
				continue;
			}
			if (ok == 0 && k_uptime_get() - start > SNIFF_ROTATE_MS) {
				break;
			}
			if (ok && k_uptime_get() - last_ok > SNIFF_LOST_MS) {
				break;
			}
		}
		idx = (idx + 1) % ARRAY_SIZE(bauds);
	}
}

static void rs485_thread(void *a, void *b, void *c)
{
	ARG_UNUSED(a);
	ARG_UNUSED(b);
	ARG_UNUSED(c);
	if (IS_ENABLED(CONFIG_BATMON_RS485_LISTEN_ONLY)) {
		sniff_loop();
	} else {
		poll_loop();
	}
}

int rs485_init(void)
{
	if (!device_is_ready(uart_dev)) {
		LOG_ERR("UART not ready");
		return -ENODEV;
	}
	if (de_gpio.port != NULL) {
		if (!device_is_ready(de_gpio.port)) {
			LOG_ERR("DE GPIO not ready");
			return -ENODEV;
		}
		gpio_pin_configure_dt(&de_gpio, GPIO_OUTPUT_INACTIVE);
	}
	set_baud(CONFIG_BATMON_RS485_BAUD ? CONFIG_BATMON_RS485_BAUD : 9600);
	uart_irq_callback_user_data_set(uart_dev, uart_isr, NULL);
	uart_irq_rx_enable(uart_dev);

	k_thread_create(&rs485_thread_data, batmon_rs485_stack, K_THREAD_STACK_SIZEOF(batmon_rs485_stack),
			rs485_thread, NULL, NULL, NULL, THREAD_PRIO, 0, K_NO_WAIT);
	k_thread_name_set(&rs485_thread_data, "rs485");
	app.rs485_present = true;
	LOG_INF("RS485 on %s, DE %s, %s", uart_dev->name, de_gpio.port ? "via GPIO" : "automatic",
		IS_ENABLED(CONFIG_BATMON_RS485_LISTEN_ONLY) ? "listen-only" : "polling");
	return 0;
}
```

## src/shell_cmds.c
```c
#include <zephyr/kernel.h>
#include <zephyr/shell/shell.h>
#include <zephyr/drivers/can.h>

#include <stdlib.h>
#include <string.h>

#include "app.h"

static int cmd_status(const struct shell *sh, size_t argc, char **argv)
{
	ARG_UNUSED(argc);
	ARG_UNUSED(argv);
	static struct bm_proto s;

	app_proto_snapshot(&s);
	const struct bm_pack_state *st = &s.st;

	shell_print(sh, "link %s, %u frames, can state %d, dropped %u, tx err %u",
		    s.link_up ? "up" : "down", (unsigned int)s.frames_total, app.can_state,
		    (unsigned int)app.can_rx_dropped, (unsigned int)app.can_tx_errors);
	shell_print(sh, "proto: %s / %s / \"%s\" mfr=\"%s\" conf=%u hints=0x%03x",
		    bm_family_name(s.det.family), bm_vendor_name(s.det.vendor), s.det.flavor,
		    st->manufacturer, s.det.confidence, (unsigned int)s.det.hints);
	shell_print(sh, "inverter: %s ident=\"%s\" heartbeats=%u", s.inv.seen ? "seen" : "none",
		    s.inv.ident, (unsigned int)s.inv.hb_count);
	shell_print(sh, "pack: %d mV  %d mA  %d.%d C  SoC %u%%  SoH %u%%  modules %u",
		    (int)st->pack_mv, (int)st->pack_ma, (int)st->temp_dc / 10,
		    (int)(st->temp_dc < 0 ? -st->temp_dc : st->temp_dc) % 10, st->soc_pct,
		    st->soh_pct, st->module_count);
	shell_print(sh, "limits: CVL %d mV  DVL %d mV  CCL %d mA  DCL %d mA", (int)st->cvl_mv,
		    (int)st->dvl_mv, (int)st->ccl_ma, (int)st->dcl_ma);
	shell_print(sh, "flags: chg %d dis %d force %d/%d full %d  prot %02x%02x alarm %02x%02x",
		    st->charge_en, st->discharge_en, st->force_charge_1, st->force_charge_2,
		    st->full_charge_req, st->prot[0], st->prot[1], st->alarm[0], st->alarm[1]);
	shell_print(sh, "net: %s %s  mqtt %s  published %u  errors %u", app.net_up ? "up" : "down",
		    app.ip, app.mqtt_connected ? "connected" : "offline",
		    (unsigned int)app.mqtt_pub_count, (unsigned int)app.mqtt_errors);
	if (app.rs485_present) {
		shell_print(sh, "rs485: %s (%s, link %s)", app.serial.flavor_str,
			    bm_serial_phase_name(app.serial.phase), app.serial.link_up ? "up" : "down");
	}
	return 0;
}

static int cmd_ids(const struct shell *sh, size_t argc, char **argv)
{
	ARG_UNUSED(argc);
	ARG_UNUSED(argv);
	static struct bm_proto s;

	app_proto_snapshot(&s);
	uint32_t now = app_uptime_ms();

	for (unsigned int i = 0; i < s.n_ids; i++) {
		const struct bm_id_stat *x = &s.ids[i];

		shell_print(sh, "%s%03x  dlc %u  n=%u  age %u ms", x->ext ? "x" : " ",
			    (unsigned int)x->id, x->dlc, (unsigned int)x->count,
			    (unsigned int)(now - x->last_ms));
	}
	return 0;
}

static int cmd_json(const struct shell *sh, size_t argc, char **argv)
{
	static char buf[APP_JSON_MAX];
	bool flat = argc > 1 && strcmp(argv[1], "flat") == 0;
	int n = app_json(buf, sizeof(buf), flat);

	if (n < 0) {
		shell_error(sh, "buffer too small");
		return -ENOMEM;
	}
	shell_print(sh, "%s", buf);
	return 0;
}

static int cmd_raw(const struct shell *sh, size_t argc, char **argv)
{
	if (argc < 2) {
		shell_print(sh, "raw log %s", app.raw_log ? "on" : "off");
		return 0;
	}
	app.raw_log = strcmp(argv[1], "on") == 0;
	shell_print(sh, "raw log %s", app.raw_log ? "on" : "off");
	return 0;
}

static int cmd_hb(const struct shell *sh, size_t argc, char **argv)
{
	if (argc < 2) {
		shell_print(sh, "bench heartbeat %s", app.bench_heartbeat ? "on" : "off");
		return 0;
	}
	int rc = can_rx_set_heartbeat(strcmp(argv[1], "on") == 0);

	if (rc == -EACCES) {
		shell_error(sh, "not available: built with BATMON_CAN_LISTEN_ONLY");
		return rc;
	}
	shell_print(sh, "bench heartbeat %s", app.bench_heartbeat ? "on" : "off");
	return 0;
}

static int cmd_reset(const struct shell *sh, size_t argc, char **argv)
{
	ARG_UNUSED(argc);
	ARG_UNUSED(argv);
	k_mutex_lock(&app.lock, K_FOREVER);
	bm_proto_init(&app.proto);
	k_mutex_unlock(&app.lock);
	shell_print(sh, "protocol state cleared");
	return 0;
}

#ifdef CONFIG_BATMON_MQTT
static int cmd_publish(const struct shell *sh, size_t argc, char **argv)
{
	ARG_UNUSED(argc);
	ARG_UNUSED(argv);
	net_mqtt_publish_now();
	shell_print(sh, "publish requested");
	return 0;
}
#endif

#ifdef CONFIG_BATMON_RS485
static void print_fixed(char *out, size_t len, int32_t v, uint32_t div, int digits)
{
	bool neg = v < 0;
	uint32_t u = neg ? (uint32_t)(-(int64_t)v) : (uint32_t)v;

	snprintf(out, len, "%s%u.%0*u", neg ? "-" : "", (unsigned int)(u / div), digits,
		 (unsigned int)(u % div));
}

static int cmd_rs_status(const struct shell *sh, size_t argc, char **argv)
{
	ARG_UNUSED(argc);
	ARG_UNUSED(argv);
	static struct bm_serial s;
	char a[16], b[16], c[16], d[16];

	app_serial_snapshot(&s);
	const struct bm_serial_state *st = &s.st;

	shell_print(sh, "rs485: %s", s.flavor_str);
	shell_print(sh, "phase %s  link %s  baud %u  ver %02x  addr %u", bm_serial_phase_name(s.phase),
		    s.link_up ? "up" : "down", (unsigned int)s.baud, s.ver, s.adr);
	shell_print(sh, "ok %u  err %u  timeouts %u  crc %u  sniffed %u  last error: %s",
		    (unsigned int)s.ok_count, (unsigned int)s.err_count,
		    (unsigned int)s.timeout_count, (unsigned int)s.crc_errors,
		    (unsigned int)s.sniff_frames, s.last_err[0] ? s.last_err : "-");
	if (st->valid & BM_SV_IDENT) {
		shell_print(sh, "model \"%s\"  manufacturer \"%s\"  sw %s  serial \"%s\"", st->model,
			    st->manufacturer, st->sw_version, st->serial);
	}
	if (st->valid & BM_SV_MEAS) {
		print_fixed(a, sizeof(a), st->pack_mv / 10, 100, 2);
		print_fixed(b, sizeof(b), st->pack_ma / 10, 100, 2);
		shell_print(sh, "pack %s V  %s A", a, b);
	}
	if (st->valid & (BM_SV_SOC | BM_SV_SOH)) {
		print_fixed(a, sizeof(a), st->soc_dpct, 10, 1);
		print_fixed(b, sizeof(b), st->soh_dpct, 10, 1);
		shell_print(sh, "SoC %s %%%s  SoH %s %%", a, st->soc_derived ? " (derived)" : "",
			    (st->valid & BM_SV_SOH) ? b : "-");
	}
	if (st->valid & BM_SV_CAP) {
		print_fixed(a, sizeof(a), (int32_t)(st->remain_mah / 10), 100, 2);
		print_fixed(b, sizeof(b), (int32_t)(st->full_mah / 10), 100, 2);
		print_fixed(c, sizeof(c), (int32_t)(st->rated_mah / 10), 100, 2);
		shell_print(sh, "capacity %s / %s Ah (rated %s)  cycles %u", a, b, c, st->cycles);
	}
	if (st->valid & BM_SV_CELLS) {
		unsigned int imin = 0, imax = 0;

		for (unsigned int i = 1; i < st->n_cells; i++) {
			if (st->cell_mv[i] < st->cell_mv[imin]) {
				imin = i;
			}
			if (st->cell_mv[i] > st->cell_mv[imax]) {
				imax = i;
			}
		}
		shell_print(sh, "cells %u: min %u mV (#%u)  max %u mV (#%u)  diff %u mV", st->n_cells,
			    st->cell_mv[imin], imin + 1, st->cell_mv[imax], imax + 1,
			    st->cell_mv[imax] - st->cell_mv[imin]);
	}
	if (st->valid & BM_SV_TEMPS) {
		char line[96] = "temps:";
		size_t len = strlen(line);

		for (unsigned int i = 0; i < st->n_temps && len < sizeof(line) - 10; i++) {
			print_fixed(a, sizeof(a), st->temp_dc[i], 10, 1);
			len += (size_t)snprintf(line + len, sizeof(line) - len, " %s", a);
		}
		shell_print(sh, "%s C", line);
	}
	if (st->valid & BM_SV_LIMITS) {
		print_fixed(a, sizeof(a), st->cvl_mv / 10, 100, 2);
		print_fixed(b, sizeof(b), st->dvl_mv / 10, 100, 2);
		print_fixed(c, sizeof(c), st->ccl_ma / 100, 10, 1);
		print_fixed(d, sizeof(d), st->dcl_ma / 100, 10, 1);
		shell_print(sh, "limits CVL %s V  DVL %s V  CCL %s A  DCL %s A  flags %02x", a, b, c, d,
			    st->req_flags);
	}
	if (st->valid & BM_SV_STATUS) {
		char hex[2 * BM_SER_STATUS_RAW + 1];

		bm_hex_encode(st->status_raw, st->n_status_raw, hex, sizeof(hex));
		shell_print(sh, "status raw: %s", hex);
	}
	if (st->valid & BM_SV_JKFLAGS) {
		shell_print(sh, "jk alarm %04x  status %04x", st->jk_alarm, st->jk_status);
	}
	return 0;
}

static int cmd_rs_cells(const struct shell *sh, size_t argc, char **argv)
{
	ARG_UNUSED(argc);
	ARG_UNUSED(argv);
	static struct bm_serial s;

	app_serial_snapshot(&s);
	if (!(s.st.valid & BM_SV_CELLS)) {
		shell_print(sh, "no cell data");
		return 0;
	}
	for (unsigned int i = 0; i < s.st.n_cells; i++) {
		shell_print(sh, "cell %2u  %u mV%s", i + 1, s.st.cell_mv[i],
			    (s.st.valid & BM_SV_STATUS) && s.st.cell_status[i] ? "  (warn)" : "");
	}
	return 0;
}

static int cmd_rs_probe(const struct shell *sh, size_t argc, char **argv)
{
	ARG_UNUSED(argc);
	ARG_UNUSED(argv);
	k_mutex_lock(&app.lock, K_FOREVER);
	bm_serial_restart(&app.serial);
	k_mutex_unlock(&app.lock);
	shell_print(sh, "rs485 detection restarted");
	return 0;
}

static void print_reply(const struct shell *sh, const uint8_t *rx, int n)
{
	if (n <= 0) {
		shell_print(sh, "no reply (%d)", n);
		return;
	}
	if (rx[0] == '~') {
		struct bm_ydt_frame f;
		static uint8_t info[BM_YDT_MAX_INFO];
		static char hex[2 * BM_YDT_MAX_INFO + 1];

		shell_print(sh, "%.*s", n - (rx[n - 1] == '\r' ? 1 : 0), (const char *)rx);
		int rc = bm_ydt_parse((const char *)rx, (size_t)n, &f, info, sizeof(info));

		if (rc) {
			shell_error(sh, "frame error %d", rc);
			return;
		}
		bm_hex_encode(info, f.info_len, hex, sizeof(hex));
		shell_print(sh, "ver %02x addr %02x cid1 %02x rtn %02x (%s) info %u bytes: %s", f.ver,
			    f.adr, f.cid1, f.cid2, bm_ydt_rtn_name(f.cid2), (unsigned int)f.info_len,
			    hex);
		return;
	}
	shell_hexdump(sh, rx, (size_t)n);
}

static int cmd_rs_cmd(const struct shell *sh, size_t argc, char **argv)
{
	static uint8_t tx[BM_SER_REQ_MAX * 4], rx[BM_SER_MAX_FRAME], info[64];
	static struct bm_serial s;
	size_t info_len = 0;

	app_serial_snapshot(&s);
	uint8_t cid2 = (uint8_t)strtoul(argv[1], NULL, 16);

	if (argc > 2) {
		int n = bm_hex_decode(argv[2], strlen(argv[2]), info, sizeof(info));

		if (n < 0) {
			shell_error(sh, "info must be hex bytes");
			return -EINVAL;
		}
		info_len = (size_t)n;
	}
	int n = bm_serial_build_cmd(&s, cid2, info, info_len, tx, sizeof(tx));

	if (n < 0) {
		return -EINVAL;
	}
	uint32_t baud = s.baud ? s.baud : 9600;

	shell_print(sh, "-> %.*s  (%u bit/s)", n - 1, (const char *)tx, (unsigned int)baud);
	int r = rs485_transact(tx, (size_t)n, BM_SER_KIND_ASCII, baud, rx, sizeof(rx),
			       bm_serial_timeout_ms(baud, BM_SER_KIND_ASCII));

	if (r == -EACCES) {
		shell_error(sh, "listen-only build");
		return r;
	}
	print_reply(sh, rx, r);
	return 0;
}

static int cmd_rs_send(const struct shell *sh, size_t argc, char **argv)
{
	static uint8_t tx[BM_SER_MAX_FRAME], rx[BM_SER_MAX_FRAME];
	size_t len;
	enum bm_ser_kind kind;
	uint32_t baud = app.serial.baud ? app.serial.baud : 9600;

	if (argc > 2) {
		baud = (uint32_t)strtoul(argv[2], NULL, 10);
	}
	if (argv[1][0] == '~') {
		len = strlen(argv[1]);
		if (len + 1 >= sizeof(tx)) {
			return -EINVAL;
		}
		memcpy(tx, argv[1], len);
		tx[len++] = '\r';
		kind = BM_SER_KIND_ASCII;
	} else {
		int n = bm_hex_decode(argv[1], strlen(argv[1]), tx, sizeof(tx));

		if (n <= 0) {
			shell_error(sh, "argument must start with ~ or be hex bytes");
			return -EINVAL;
		}
		len = (size_t)n;
		kind = (tx[0] == 0x4E) ? BM_SER_KIND_JK : BM_SER_KIND_MODBUS;
	}
	int r = rs485_transact(tx, len, kind, baud, rx, sizeof(rx), bm_serial_timeout_ms(baud, kind));

	if (r == -EACCES) {
		shell_error(sh, "listen-only build");
		return r;
	}
	print_reply(sh, rx, r);
	return 0;
}

static int cmd_rs_last(const struct shell *sh, size_t argc, char **argv)
{
	ARG_UNUSED(argc);
	ARG_UNUSED(argv);
	static struct bm_serial s;

	app_serial_snapshot(&s);
	if (s.last_rx_len == 0) {
		shell_print(sh, "nothing received yet");
		return 0;
	}
	print_reply(sh, s.last_rx, (int)s.last_rx_len);
	return 0;
}

SHELL_STATIC_SUBCMD_SET_CREATE(sub_rs485,
	SHELL_CMD(status, NULL, "RS485 link, detection and decoded values", cmd_rs_status),
	SHELL_CMD(cells, NULL, "Cell voltages", cmd_rs_cells),
	SHELL_CMD(probe, NULL, "Restart protocol detection", cmd_rs_probe),
	SHELL_CMD_ARG(cmd, NULL, "Send <cid2 hex> [info hex] with the detected VER/ADR", cmd_rs_cmd, 2, 1),
	SHELL_CMD_ARG(send, NULL, "Send raw: ~ASCII frame (CR added) or hex bytes [baud]", cmd_rs_send,
		      2, 1),
	SHELL_CMD(last, NULL, "Last received frame", cmd_rs_last),
	SHELL_SUBCMD_SET_END);
#endif /* CONFIG_BATMON_RS485 */

SHELL_STATIC_SUBCMD_SET_CREATE(sub_batmon,
	SHELL_CMD(status, NULL, "Decoded battery state and link status", cmd_status),
	SHELL_CMD(ids, NULL, "CAN identifiers seen so far", cmd_ids),
	SHELL_CMD_ARG(json, NULL, "Telemetry JSON [flat]", cmd_json, 1, 1),
	SHELL_CMD_ARG(raw, NULL, "Raw frame logging on|off", cmd_raw, 1, 1),
	SHELL_CMD_ARG(hb, NULL, "Bench heartbeat 0x305 on|off", cmd_hb, 1, 1),
	SHELL_CMD(reset, NULL, "Clear decoded state and detection", cmd_reset),
#ifdef CONFIG_BATMON_MQTT
	SHELL_CMD(publish, NULL, "Publish telemetry now", cmd_publish),
#endif
#ifdef CONFIG_BATMON_RS485
	SHELL_CMD(rs485, &sub_rs485, "RS485 BMS link", NULL),
#endif
	SHELL_SUBCMD_SET_END);

SHELL_CMD_REGISTER(batmon, &sub_batmon, "batmon battery monitor", NULL);
```
